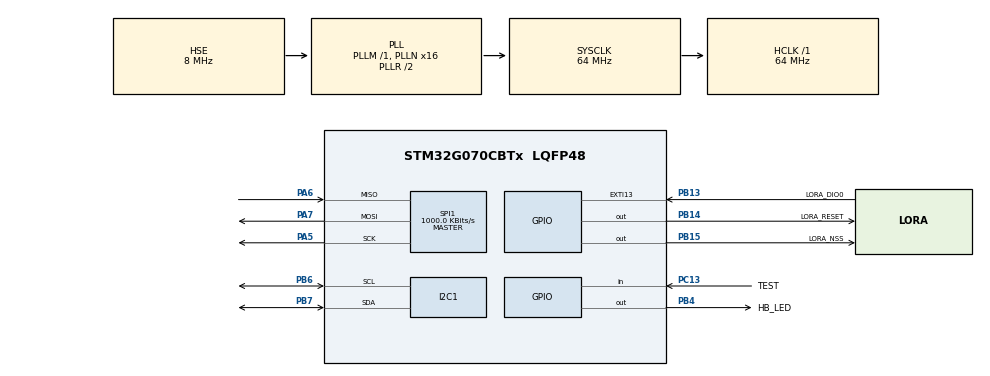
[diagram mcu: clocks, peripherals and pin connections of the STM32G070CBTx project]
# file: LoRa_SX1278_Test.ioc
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I2C1.Timing=0x10B17DB5
Mcu.Family=STM32G0
Mcu.Name=STM32G070CBTx
Mcu.Package=LQFP48
NVIC.EXTI4_15_IRQn=true\:0\:0\:false\:false\:true\:true\:true\:true
PA13.Mode=Serial_Wire
PA13.Signal=SYS_SWDIO
PA14-BOOT0.Mode=Serial_Wire
PA14-BOOT0.Signal=SYS_SWCLK
PA5.Mode=Full_Duplex_Master
PA5.Signal=SPI1_SCK
PA6.Mode=Full_Duplex_Master
PA6.Signal=SPI1_MISO
PA7.Mode=Full_Duplex_Master
PA7.Signal=SPI1_MOSI
PB13.GPIO_Label=LORA_DIO0
PB13.Signal=GPXTI13
PB14.GPIO_Label=LORA_RESET
PB14.PinState=GPIO_PIN_SET
PB14.Signal=GPIO_Output
PB15.GPIO_Label=LORA_NSS
PB15.PinState=GPIO_PIN_SET
PB15.Signal=GPIO_Output
PB4.GPIO_Label=HB_LED
PB4.PinState=GPIO_PIN_SET
PB4.Signal=GPIO_Output
PB6.GPIO_Pu=GPIO_NOPULL
PB6.GPIO_Speed=GPIO_SPEED_FREQ_HIGH
PB6.Mode=I2C
PB6.Signal=I2C1_SCL
PB7.GPIO_Pu=GPIO_NOPULL
PB7.GPIO_Speed=GPIO_SPEED_FREQ_HIGH
PB7.Mode=I2C
PB7.Signal=I2C1_SDA
PC13.GPIO_Label=TEST
PC13.GPIO_PuPd=GPIO_PULLUP
PC13.Signal=GPIO_Input
PF0-OSC_IN\ (PF0).Mode=HSE-External-Oscillator
PF0-OSC_IN\ (PF0).Signal=RCC_OSC_IN
PF1-OSC_OUT\ (PF1).Mode=HSE-External-Oscillator
PF1-OSC_OUT\ (PF1).Signal=RCC_OSC_OUT
ProjectManager.HeapSize=0x200
ProjectManager.StackSize=0x400
ProjectManager.TargetToolchain=STM32CubeIDE
RCC.ADCFreq_Value=64000000
RCC.AHBFreq_Value=64000000
RCC.CortexFreq_Value=64000000
RCC.EXTERNAL_CLOCK_VALUE=48000
RCC.HCLKFreq_Value=64000000
RCC.HSE_VALUE=8000000
RCC.HSI_VALUE=16000000
RCC.LSE_VALUE=32768
RCC.PLLN=16
RCC.PLLSourceVirtual=RCC_PLLSOURCE_HSE
RCC.SYSCLKFreq_VALUE=64000000
RCC.SYSCLKSource=RCC_SYSCLKSOURCE_PLLCLK
RCC.VCOOutputFreq_Value=128000000
SPI1.BaudRatePrescaler=SPI_BAUDRATEPRESCALER_64
SPI1.CalculateBaudRate=1000.0 KBits/s
SPI1.DataSize=SPI_DATASIZE_8BIT
SPI1.Direction=SPI_DIRECTION_2LINES
SPI1.Mode=SPI_MODE_MASTER
SPI1.NSSPMode=SPI_NSS_PULSE_DISABLE
SPI1.VirtualType=VM_MASTER
board=custom

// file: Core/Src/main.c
/* USER CODE BEGIN Header */
/**
  ******************************************************************************
  * @file           : main.c
  * @brief          : Main program body
  ******************************************************************************
  * @attention
  *
  * Copyright (c) 2026 STMicroelectronics.
  * All rights reserved.
  *
  * This software is licensed under terms that can be found in the LICENSE file
  * in the root directory of this software component.
  * If no LICENSE file comes with this software, it is provided AS-IS.
  *
  ******************************************************************************
  */
/* USER CODE END Header */
#include "main.h"

/* USER CODE BEGIN Includes */
#include "project_app.h"

/* USER CODE END Includes */

I2C_HandleTypeDef hi2c1;

SPI_HandleTypeDef hspi1;

void SystemClock_Config(void);
static void MX_GPIO_Init(void);
static void MX_I2C1_Init(void);
static void MX_SPI1_Init(void);

int main(void)
{

  /* MCU Configuration--------------------------------------------------------*/

  /* Reset of all peripherals, Initializes the Flash interface and the Systick. */
  HAL_Init();

  /* Configure the system clock */
  SystemClock_Config();

  /* Initialize all configured peripherals */
  MX_GPIO_Init();
  MX_I2C1_Init();
  MX_SPI1_Init();
  /* USER CODE BEGIN 2 */
  project_app_init(); /* Project: Initialize test display and diagnostics. */
  /* USER CODE END 2 */

  /* Infinite loop */
  while (1)
  {

    /* USER CODE BEGIN 3 */
    project_app_run(); /* Project: Service cooperative test tasks. */
  }
  /* USER CODE END 3 */
}

void SystemClock_Config(void)
{
  RCC_OscInitTypeDef RCC_OscInitStruct = {0};
  RCC_ClkInitTypeDef RCC_ClkInitStruct = {0};

  /** Configure the main internal regulator output voltage
  */
  HAL_PWREx_ControlVoltageScaling(PWR_REGULATOR_VOLTAGE_SCALE1);

  /** Initializes the RCC Oscillators according to the specified parameters
  * in the RCC_OscInitTypeDef structure.
  */
  RCC_OscInitStruct.OscillatorType = RCC_OSCILLATORTYPE_HSE;
  RCC_OscInitStruct.HSEState = RCC_HSE_ON;
  RCC_OscInitStruct.PLL.PLLState = RCC_PLL_ON;
  RCC_OscInitStruct.PLL.PLLSource = RCC_PLLSOURCE_HSE;
  RCC_OscInitStruct.PLL.PLLM = RCC_PLLM_DIV1;
  RCC_OscInitStruct.PLL.PLLN = 16;
  RCC_OscInitStruct.PLL.PLLP = RCC_PLLP_DIV2;
  RCC_OscInitStruct.PLL.PLLR = RCC_PLLR_DIV2;
  if (HAL_RCC_OscConfig(&RCC_OscInitStruct) != HAL_OK)
  {
    Error_Handler();
  }

  /** Initializes the CPU, AHB and APB buses clocks
  */
  RCC_ClkInitStruct.ClockType = RCC_CLOCKTYPE_HCLK|RCC_CLOCKTYPE_SYSCLK
                              |RCC_CLOCKTYPE_PCLK1;
  RCC_ClkInitStruct.SYSCLKSource = RCC_SYSCLKSOURCE_PLLCLK;
  RCC_ClkInitStruct.AHBCLKDivider = RCC_SYSCLK_DIV1;
  RCC_ClkInitStruct.APB1CLKDivider = RCC_HCLK_DIV1;

  if (HAL_RCC_ClockConfig(&RCC_ClkInitStruct, FLASH_LATENCY_2) != HAL_OK)
  {
    Error_Handler();
  }
}

static void MX_I2C1_Init(void)
{

  hi2c1.Instance = I2C1;
  hi2c1.Init.Timing = 0x10B17DB5;
  hi2c1.Init.OwnAddress1 = 0;
  hi2c1.Init.AddressingMode = I2C_ADDRESSINGMODE_7BIT;
  hi2c1.Init.DualAddressMode = I2C_DUALADDRESS_DISABLE;
  hi2c1.Init.OwnAddress2 = 0;
  hi2c1.Init.OwnAddress2Masks = I2C_OA2_NOMASK;
  hi2c1.Init.GeneralCallMode = I2C_GENERALCALL_DISABLE;
  hi2c1.Init.NoStretchMode = I2C_NOSTRETCH_DISABLE;
  if (HAL_I2C_Init(&hi2c1) != HAL_OK)
  {
    Error_Handler();
  }

  /** Configure Analogue filter
  */
  if (HAL_I2CEx_ConfigAnalogFilter(&hi2c1, I2C_ANALOGFILTER_ENABLE) != HAL_OK)
  {
    Error_Handler();
  }

  /** Configure Digital filter
  */
  if (HAL_I2CEx_ConfigDigitalFilter(&hi2c1, 0) != HAL_OK)
  {
    Error_Handler();
  }

}

static void MX_SPI1_Init(void)
{

  /* SPI1 parameter configuration*/
  hspi1.Instance = SPI1;
  hspi1.Init.Mode = SPI_MODE_MASTER;
  hspi1.Init.Direction = SPI_DIRECTION_2LINES;
  hspi1.Init.DataSize = SPI_DATASIZE_8BIT;
  hspi1.Init.CLKPolarity = SPI_POLARITY_LOW;
  hspi1.Init.CLKPhase = SPI_PHASE_1EDGE;
  hspi1.Init.NSS = SPI_NSS_SOFT;
  hspi1.Init.BaudRatePrescaler = SPI_BAUDRATEPRESCALER_64;
  hspi1.Init.FirstBit = SPI_FIRSTBIT_MSB;
  hspi1.Init.TIMode = SPI_TIMODE_DISABLE;
  hspi1.Init.CRCCalculation = SPI_CRCCALCULATION_DISABLE;
  hspi1.Init.CRCPolynomial = 7;
  hspi1.Init.CRCLength = SPI_CRC_LENGTH_DATASIZE;
  hspi1.Init.NSSPMode = SPI_NSS_PULSE_DISABLE;
  if (HAL_SPI_Init(&hspi1) != HAL_OK)
  {
    Error_Handler();
  }

}

static void MX_GPIO_Init(void)
{
  GPIO_InitTypeDef GPIO_InitStruct = {0};

  /* GPIO Ports Clock Enable */
  __HAL_RCC_GPIOC_CLK_ENABLE();
  __HAL_RCC_GPIOF_CLK_ENABLE();
  __HAL_RCC_GPIOA_CLK_ENABLE();
  __HAL_RCC_GPIOB_CLK_ENABLE();

  /*Configure GPIO pin Output Level */
  HAL_GPIO_WritePin(GPIOB, LORA_RESET_Pin|LORA_NSS_Pin|HB_LED_Pin, GPIO_PIN_SET);

  /*Configure GPIO pin : TEST_Pin */
  GPIO_InitStruct.Pin = TEST_Pin;
  GPIO_InitStruct.Mode = GPIO_MODE_INPUT;
  GPIO_InitStruct.Pull = GPIO_PULLUP;
  HAL_GPIO_Init(TEST_GPIO_Port, &GPIO_InitStruct);

  /*Configure GPIO pin : LORA_DIO0_Pin */
  GPIO_InitStruct.Pin = LORA_DIO0_Pin;
  GPIO_InitStruct.Mode = GPIO_MODE_IT_RISING;
  GPIO_InitStruct.Pull = GPIO_NOPULL;
  HAL_GPIO_Init(LORA_DIO0_GPIO_Port, &GPIO_InitStruct);

  /*Configure GPIO pins : LORA_RESET_Pin LORA_NSS_Pin HB_LED_Pin */
  GPIO_InitStruct.Pin = LORA_RESET_Pin|LORA_NSS_Pin|HB_LED_Pin;
  GPIO_InitStruct.Mode = GPIO_MODE_OUTPUT_PP;
  GPIO_InitStruct.Pull = GPIO_NOPULL;
  GPIO_InitStruct.Speed = GPIO_SPEED_FREQ_LOW;
  HAL_GPIO_Init(GPIOB, &GPIO_InitStruct);

  /* EXTI interrupt init*/
  HAL_NVIC_SetPriority(EXTI4_15_IRQn, 0, 0);
  HAL_NVIC_EnableIRQ(EXTI4_15_IRQn);

}

void Error_Handler(void)
{
  __disable_irq();
  while (1)
  {
  }
}
